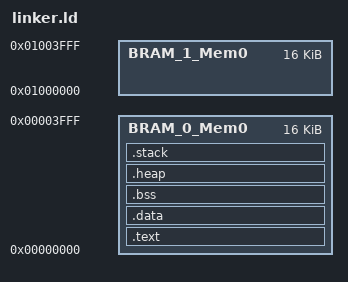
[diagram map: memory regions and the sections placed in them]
/*******************************************************************/
/*                                                                 */
/* This file is automatically generated by linker script generator.*/
/*                                                                 */
/* Version:                                 */
/*                                                                 */
/* Copyright (c) 2010-2016 Xilinx, Inc.  All rights reserved.      */
/*                                                                 */
/* Description : MicroBlaze Linker Script                          */
/*                                                                 */
/*******************************************************************/

_STACK_SIZE = DEFINED(_STACK_SIZE) ? _STACK_SIZE : 0x400;
_HEAP_SIZE = DEFINED(_HEAP_SIZE)   ? _HEAP_SIZE  : 0x800;

/* Define Memories in the system */

MEMORY
{
   BRAM_0_Mem0 : ORIGIN = 0x0, LENGTH = 0x4000
   BRAM_1_Mem0 : ORIGIN = 0x1000000, LENGTH = 0x4000
}

/* Specify the default entry point to the program */

ENTRY(_start)

/* Define the sections, and where they are mapped in memory */

SECTIONS
{

.text : {
   *(.boot)
   *(.text)
   *(.text.*)
   *(.gnu.linkonce.t.*)
} > BRAM_0_Mem0

.data : {
   . = ALIGN(4);
   __data_start = .;
   *(.data)
   *(.data.*)
   *(.gnu.linkonce.d.*)
   __data_end = .;
} > BRAM_0_Mem0

.bss (NOLOAD) : {
   . = ALIGN(4);
   __bss_start = .;
   *(.bss)
   *(.bss.*)
   *(.gnu.linkonce.b.*)
   *(COMMON)
   . = ALIGN(4);
   __bss_end = .;
} > BRAM_0_Mem0


/* Generate Stack and Heap definitions */

.heap (NOLOAD) : {
   . = ALIGN(8);
   _heap = .;
   _heap_start = .;
   . += _HEAP_SIZE;
   _heap_end = .;
} > BRAM_0_Mem0

.stack (NOLOAD) : {
   _stack_end = .;
   . += _STACK_SIZE;
   . = ALIGN(8);
   _stack = .;
   __stack = _stack;
} > BRAM_0_Mem0

_end = .;
}

